VERSION ""

NS_ :

BS_:

BU_: BMU_Master CMU_Module1 Inverter_PCS

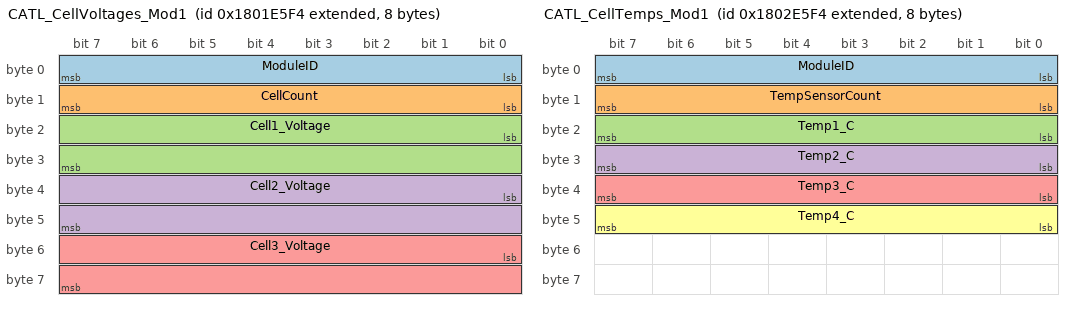
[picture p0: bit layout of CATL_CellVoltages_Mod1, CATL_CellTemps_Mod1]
BO_ 2550261236 CATL_CellVoltages_Mod1: 8 CMU_Module1
 SG_ ModuleID : 0|8@1+ (1,0) [0|255] "" BMU_Master
 SG_ CellCount : 8|8@1+ (1,0) [1|16] "" BMU_Master
 SG_ Cell1_Voltage : 16|16@1+ (0.001,0) [0|5] "V" BMU_Master
 SG_ Cell2_Voltage : 32|16@1+ (0.001,0) [0|5] "V" BMU_Master
 SG_ Cell3_Voltage : 48|16@1+ (0.001,0) [0|5] "V" BMU_Master

BO_ 2550326772 CATL_CellTemps_Mod1: 8 CMU_Module1
 SG_ ModuleID : 0|8@1+ (1,0) [0|255] "" BMU_Master
 SG_ TempSensorCount : 8|8@1+ (1,0) [1|8] "" BMU_Master
 SG_ Temp1_C : 16|8@1+ (1,-40) [-40|120] "degC" BMU_Master
 SG_ Temp2_C : 24|8@1+ (1,-40) [-40|120] "degC" BMU_Master
 SG_ Temp3_C : 32|8@1+ (1,-40) [-40|120] "degC" BMU_Master
 SG_ Temp4_C : 40|8@1+ (1,-40) [-40|120] "degC" BMU_Master

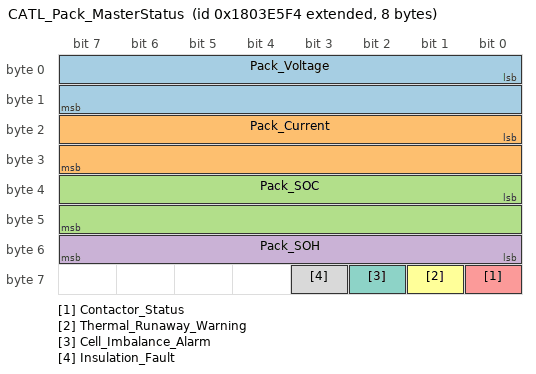
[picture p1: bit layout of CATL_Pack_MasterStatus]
BO_ 2550392308 CATL_Pack_MasterStatus: 8 BMU_Master
 SG_ Pack_Voltage : 0|16@1+ (0.1,0) [0|1500] "V" Inverter_PCS
 SG_ Pack_Current : 16|16@1+ (0.1,-500) [-500|500] "A" Inverter_PCS
 SG_ Pack_SOC : 32|16@1+ (0.1,0) [0|100] "%" Inverter_PCS
 SG_ Pack_SOH : 48|8@1+ (1,0) [0|100] "%" Inverter_PCS
 SG_ Contactor_Status : 56|1@1+ (1,0) [0|1] "" Inverter_PCS
 SG_ Thermal_Runaway_Warning : 57|1@1+ (1,0) [0|1] "" Inverter_PCS
 SG_ Cell_Imbalance_Alarm : 58|1@1+ (1,0) [0|1] "" Inverter_PCS
 SG_ Insulation_Fault : 59|1@1+ (1,0) [0|1] "" Inverter_PCS

CM_ BO_ 2550261236 "Trama de medicion de voltajes celda a celda CATL EnerOne 314Ah";
CM_ BO_ 2550326772 "Arreglo de sensores NTC termicos de celda y busbar";
CM_ BO_ 2550392308 "Estado general de potencia, corriente y banderas de seguridad de rack";
